# YTM32B1HA0 register map
Vendor: YTMicro; File version: 1.0
CPU: little endian, MPU, FPU, 2 interrupt priority bits
Registers are 32-bit, read-write, reset 0x0 unless marked. A register's access mark holds for its fields unless they carry their own. Offsets are from the block's base; [hi:lo] are bit positions; {n}, {i} and the like mark numbered series; 'fields as' and 'values as' point back to an identical list.

## WKU — Wake-up Unit
Base 0x40188000; register names take the prefix WKU_
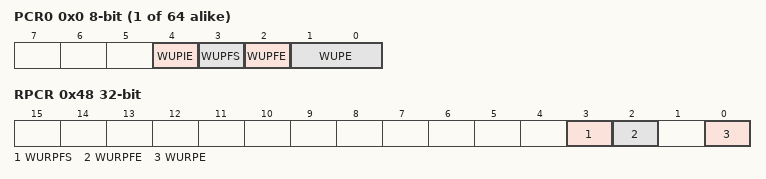
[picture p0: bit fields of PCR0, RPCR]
{0x0+i} PCR{i} 8-bit (i=0..63) — This register includes the field to enable and select the edge detect type for the external wake-up input pins.
  [4] WUPIE — Interrupt should always be enabled when pin selected as wake-up source
    0=wake-up pin interrupt is disabled; 1=wake-up pin interrupt is enabled
  [3] WUPFS — Select wake-up pin filter clock source.
    0=SIRC clock is selected as wake-up in filter clock source; 1=SXOSC clock is selected as wake-up in filter clock source
  [2] WUPFE — Enables the digital filter for the external pin detect.
    0=Filter disabled; 1=Filter enabled
  [1:0] WUPE — Enables and configures the edge detection for the wake-up pin.
    0=External input pin disabled as wake-up input; 1=External input pin enabled with rising edge detection; 2=External input pin enabled with falling edge detection; 3=External input pin enabled with rising or falling edge detection
0x40 PFR0 — The PFR register contains the wake-up flags indicating which wake-up source caused the MCU to exit Power Down mode. The external wake-up flags are read-only and clearing a flag is accomplished by a write of a 1 to the corresponding WUFn bit. The wake-up flag (WUFn), if set, will remain set if the associated WUPEn bit is cleared.
  [31:0] WUF — Indicates that an enabled external wake-up pin was a source of exiting a Power Down mode. To clear the flag write a one to WUFn.
    0b=0b (WKU_Pn input was not a wake-up source); 1b=1b (WKU_Pn input was a wake-up source)
0x44 PFR1 — The PFR register contains the wake-up flags indicating which wake-up source caused the MCU to exit Power Down mode. The external wake-up flags are read-only and clearing a flag is accomplished by a write of a 1 to the corresponding WUFn bit. The wake-up flag (WUFn), if set, will remain set if the associated WUPEn bit is cleared.
  fields as PFR0
0x48 RPCR — This register controls the reset pin filter functions.
  [3] WURPFS — Select Reset pin filter clock source.
    0=SIRC clock is selected as Reset pin filter clock source; 1=SXOSC clock is selected as Reset pin filter clock source
  [2] WURPFE — Enable bit of Reset pin filter, this bit should be set if filter need to be used.
    0=Disable reset pin filter; 1=Enable reset pin filter
  [0] WURPE — Enable Reset pin as a wake-up source input.
    0=Reset pin not used as wake-up source; 1=Reset pin used as wake-up source
0x4C MER — This register contains the bits to enable an internal module interrupt as a wake-up source.
  [4:0] WUME — 0b00001 - RTC_IRQ 0b00010 - RTC_Seconds_IRQ 0b00100 - lpTMR0_IRQ 0b01000 - ACMP0_IRQ 0b10000 - ACMP1_IRQ

## TMR0
Base 0x40150000; register names take the prefix TMR0_
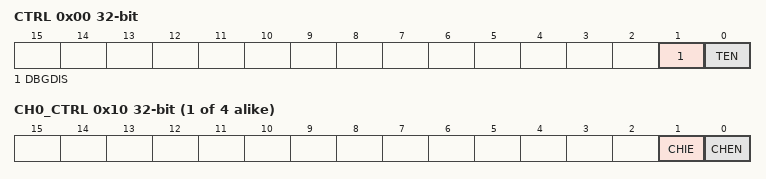
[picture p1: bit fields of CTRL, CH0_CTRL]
0x00 CTRL
  [1] DBGDIS — Stops the timer when the chip enters debug mode.
    0=The timer runs in debug mode; 1=The timer stops in debug mode
  [0] TEN — Enable the timer.
    0=The timer is disabled; 1=The timer is enabled
0x04 PRS
  [7:0] PRS — Selects the module clock divide value for the prescaler (1–256). The module clock is divided by (PRS + 1)
0x08 CNT — Holds the timer count value.
  [31:0] CNT — The time base for all compare channels. When enabled, the timer count increments at the rate of the module clock divided by the prescale value. Writing operation to this register will load writing value to it immediately.
{0x10+0x10*i} CH{i}_CTRL (i=0..3)
  [1] CHIE
    0=Channel interrupt is disabled; 1=Channel interrupt is enabled
  [0] CHEN
    0=Channel is disabled; 1=Channel is enabled
{0x14+0x10*i} CH{i}_INT (i=0..3)
  [0] CHIF — Indicates the channel interrupt is asserted due to a match on the channel. Write 1 to clear it.
    0=Channel interrupt is not asserted; 1=Channel interrupt is asserted
{0x18+0x10*i} CH{i}_CMP (i=0..3)
  [31:0] CHCMP — If the channel is enabled (CH_CTRL[CHEN]), when the timer count (CNT) matches this value, TMR sets the channel interrupt flag (CH_INT[CHIF]). If the channel interrupt is enabled (CH_CTRL[CHIE]), TMR asserts the channel interrupt.

## TMR1
Base 0x40154000; register names take the prefix TMR1_
Registers as TMR0.
